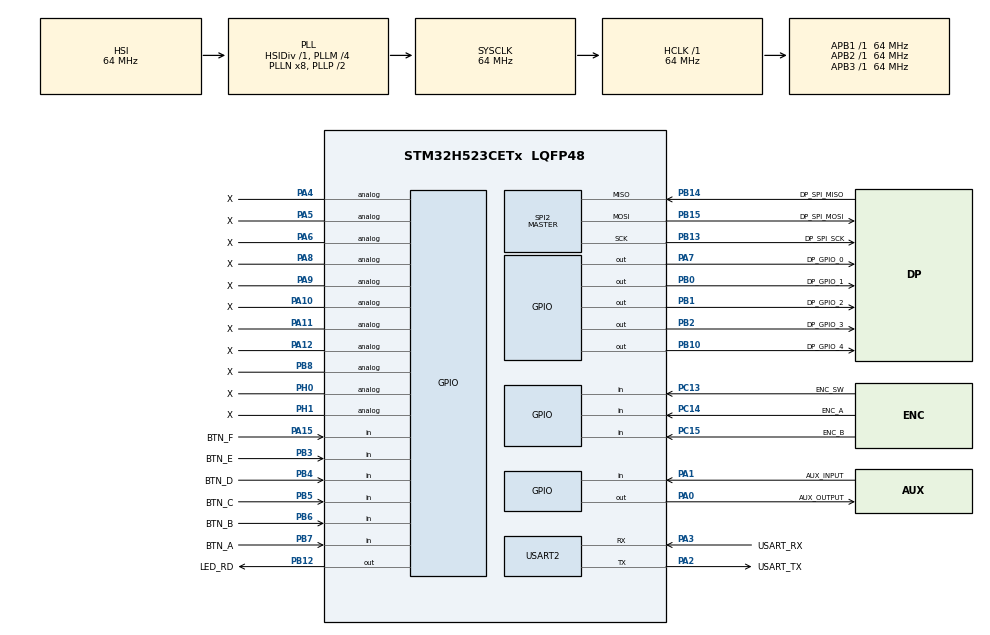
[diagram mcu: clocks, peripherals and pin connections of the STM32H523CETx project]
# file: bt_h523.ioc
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BOOTPATH.BootPathName=LEGACY
BOOTPATH.UserSelectedBootPath=LEGACY
CORTEX_M33_NS.Number-Cortex_Memory_Protection_Unit_Region0_OTP_RO_AREAS_Settings=MPU_REGION_NUMBER0
CORTEX_M33_NS.default_mode_Activation=1
CORTEX_M33_NS.userName=CORTEX_M33
GPDMA1.DIRECTION_GPDMACH3=DMA_MEMORY_TO_PERIPH
GPDMA1.IPHANDLE_GPDMACH2-SIMPLEREQUEST_GPDMACH2=__NULL
GPDMA1.IPHANDLE_GPDMACH3-SIMPLEREQUEST_GPDMACH3=__NULL
GPDMA1.REQUEST_GPDMACH2=GPDMA1_REQUEST_USART2_TX
GPDMA1.REQUEST_GPDMACH3=GPDMA1_REQUEST_USART2_RX
Mcu.Family=STM32H5
Mcu.Name=STM32H523CETx
Mcu.Package=LQFP48
NVIC.GPDMA1_Channel2_IRQn=true\:0\:0\:false\:false\:true\:false\:true\:true
NVIC.GPDMA1_Channel3_IRQn=true\:0\:0\:false\:false\:true\:false\:true\:true
NVIC.PriorityGroup=NVIC_PRIORITYGROUP_4
NVIC.USART2_IRQn=true\:0\:0\:false\:false\:true\:true\:true\:true
PA0.GPIO_Label=AUX_OUTPUT
PA0.Signal=GPIO_Output
PA1.GPIO_Label=AUX_INPUT
PA1.Signal=GPIO_Input
PA10.GPIO_Label=X
PA10.GPIO_Mode=GPIO_MODE_ANALOG
PA10.GPIO_Pd=GPIO_PULLDOWN
PA10.Signal=GPIO_Analog
PA11.GPIO_Label=X
PA11.GPIO_Mode=GPIO_MODE_ANALOG
PA11.GPIO_Pd=GPIO_PULLDOWN
PA11.Signal=GPIO_Analog
PA12.GPIO_Label=X
PA12.GPIO_Mode=GPIO_MODE_ANALOG
PA12.GPIO_Pd=GPIO_PULLDOWN
PA12.Signal=GPIO_Analog
PA13(JTMS/SWDIO).Mode=Serial_Wire
PA13(JTMS/SWDIO).Signal=DEBUG_JTMS-SWDIO
PA14(JTCK/SWCLK).Mode=Serial_Wire
PA14(JTCK/SWCLK).Signal=DEBUG_JTCK-SWCLK
PA15(JTDI).GPIO_Label=BTN_F
PA15(JTDI).Signal=GPIO_Input
PA2.GPIO_Label=USART_TX
PA2.Mode=Asynchronous
PA2.Signal=USART2_TX
PA3.GPIO_Label=USART_RX
PA3.Mode=Asynchronous
PA3.Signal=USART2_RX
PA4.GPIO_Label=X
PA4.GPIO_Mode=GPIO_MODE_ANALOG
PA4.GPIO_Pd=GPIO_PULLDOWN
PA4.Signal=GPIO_Analog
PA5.GPIO_Label=X
PA5.GPIO_Mode=GPIO_MODE_ANALOG
PA5.GPIO_Pd=GPIO_PULLDOWN
PA5.Signal=GPIO_Analog
PA6.GPIO_Label=X
PA6.GPIO_Mode=GPIO_MODE_ANALOG
PA6.GPIO_Pd=GPIO_PULLDOWN
PA6.Signal=GPIO_Analog
PA7.GPIO_Label=DP_GPIO_0
PA7.Signal=GPIO_Output
PA8.GPIO_Label=X
PA8.GPIO_Mode=GPIO_MODE_ANALOG
PA8.GPIO_Pd=GPIO_PULLDOWN
PA8.Signal=GPIO_Analog
PA9.GPIO_Label=X
PA9.GPIO_Mode=GPIO_MODE_ANALOG
PA9.GPIO_Pd=GPIO_PULLDOWN
PA9.Signal=GPIO_Analog
PB0.GPIO_Label=DP_GPIO_1
PB0.Signal=GPIO_Output
PB1.GPIO_Label=DP_GPIO_2
PB1.Signal=GPIO_Output
PB10.GPIO_Label=DP_GPIO_4
PB10.Signal=GPIO_Output
PB12.GPIO_Label=LED_RD
PB12.Signal=GPIO_Output
PB13.GPIO_Label=DP_SPI_SCK
PB13.Mode=Full_Duplex_Master
PB13.Signal=SPI2_SCK
PB14.GPIO_Label=DP_SPI_MISO
PB14.Mode=Full_Duplex_Master
PB14.Signal=SPI2_MISO
PB15.GPIO_Label=DP_SPI_MOSI
PB15.Mode=Full_Duplex_Master
PB15.Signal=SPI2_MOSI
PB2.GPIO_Label=DP_GPIO_3
PB2.Signal=GPIO_Output
PB3(JTDO/TRACESWO).GPIO_Label=BTN_E
PB3(JTDO/TRACESWO).Signal=GPIO_Input
PB4(NJTRST).GPIO_Label=BTN_D
PB4(NJTRST).Signal=GPIO_Input
PB5.GPIO_Label=BTN_C
PB5.Signal=GPIO_Input
PB6.GPIO_Label=BTN_B
PB6.Signal=GPIO_Input
PB7.GPIO_Label=BTN_A
PB7.Signal=GPIO_Input
PB8.GPIO_Label=X
PB8.GPIO_Mode=GPIO_MODE_ANALOG
PB8.GPIO_Pd=GPIO_PULLDOWN
PB8.Signal=GPIO_Analog
PC13.GPIO_Label=ENC_SW
PC13.Signal=GPIO_Input
PC14-OSC32_IN(OSC32_IN).GPIO_Label=ENC_A
PC14-OSC32_IN(OSC32_IN).Signal=GPIO_Input
PC15-OSC32_OUT(OSC32_OUT).GPIO_Label=ENC_B
PC15-OSC32_OUT(OSC32_OUT).Signal=GPIO_Input
PH0-OSC_IN(PH0).GPIO_Label=X
PH0-OSC_IN(PH0).GPIO_Mode=GPIO_MODE_ANALOG
PH0-OSC_IN(PH0).GPIO_Pd=GPIO_PULLDOWN
PH0-OSC_IN(PH0).Signal=GPIO_Analog
PH1-OSC_OUT(PH1).GPIO_Label=X
PH1-OSC_OUT(PH1).GPIO_Mode=GPIO_MODE_ANALOG
PH1-OSC_OUT(PH1).GPIO_Pd=GPIO_PULLDOWN
PH1-OSC_OUT(PH1).Signal=GPIO_Analog
ProjectManager.HeapSize=0x200
ProjectManager.StackSize=0x400
ProjectManager.TargetToolchain=CMake
RCC.ADCFreq_Value=64000000
RCC.AHBFreq_Value=64000000
RCC.APB1Freq_Value=64000000
RCC.APB1TimFreq_Value=64000000
RCC.APB2Freq_Value=64000000
RCC.APB2TimFreq_Value=64000000
RCC.APB3Freq_Value=64000000
RCC.CSI_VALUE=4000000
RCC.CortexFreq_Value=64000000
RCC.EPOD_VALUE=64000000
RCC.HCLKFreq_Value=64000000
RCC.HSE_VALUE=25000000
RCC.HSI48_VALUE=48000000
RCC.HSIDiv=RCC_HSI_DIV1
RCC.HSI_VALUE=64000000
RCC.LSE_VALUE=32768
RCC.LSIRC_VALUE=32000
RCC.PLL1Q=3
RCC.PLL2FRACN=0
RCC.PLL3FRACN=0
RCC.PLLFRACN=0
RCC.PLLM=4
RCC.PLLN=8
RCC.PLLSourceVirtual=RCC_PLL1_SOURCE_HSI
RCC.SYSCLKFreq_VALUE=64000000
RCC.SYSCLKSource=RCC_SYSCLKSOURCE_PLLCLK
RCC.USBFreq_Value=48000000
RCC.VCOOutputFreq_Value=128000000
SPI2.CalculateBaudRate=21.333332 MBits/s
SPI2.Direction=SPI_DIRECTION_2LINES
SPI2.Mode=SPI_MODE_MASTER
SPI2.VirtualType=VM_MASTER
USART2.VirtualMode-Asynchronous=VM_ASYNC
VP_BOOTPATH_VS_BOOTPATH.Mode=BP_Activate
VP_CORTEX_M33_NS_VS_Hclk.Mode=Hclk_Mode
VP_GPDMA1_VS_GPDMACH2.Mode=SIMPLEREQUEST_GPDMACH2
VP_GPDMA1_VS_GPDMACH3.Mode=SIMPLEREQUEST_GPDMACH3
VP_ICACHE_VS_ICACHE.Mode=DirectMappedCache
VP_MEMORYMAP_VS_MEMORYMAP.Mode=CurAppReg
VP_PWR_VS_LPOM.Mode=PowerOptimisation
VP_PWR_VS_SECSignals.Mode=Security/Privilege
board=custom

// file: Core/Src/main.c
/* USER CODE BEGIN Header */
/**
  ******************************************************************************
  * @file           : main.c
  * @brief          : Main program body
  ******************************************************************************
  * @attention
  *
  * Copyright (c) 2026 STMicroelectronics.
  * All rights reserved.
  *
  * This software is licensed under terms that can be found in the LICENSE file
  * in the root directory of this software component.
  * If no LICENSE file comes with this software, it is provided AS-IS.
  *
  ******************************************************************************
  */
/* USER CODE END Header */
#include "main.h"

SPI_HandleTypeDef hspi2;

UART_HandleTypeDef huart2;
DMA_HandleTypeDef handle_GPDMA1_Channel3;
DMA_HandleTypeDef handle_GPDMA1_Channel2;

void SystemClock_Config(void);
static void MPU_Config(void);
static void MX_GPIO_Init(void);
static void MX_GPDMA1_Init(void);
static void MX_ICACHE_Init(void);
static void MX_USART2_UART_Init(void);
static void MX_SPI2_Init(void);

int main(void)
{

  /* MCU Configuration--------------------------------------------------------*/

  /* MPU Configuration--------------------------------------------------------*/
  MPU_Config();

  /* Reset of all peripherals, Initializes the Flash interface and the Systick. */
  HAL_Init();

  /* Configure the system clock */
  SystemClock_Config();

  /* Initialize all configured peripherals */
  MX_GPIO_Init();
  MX_GPDMA1_Init();
  MX_ICACHE_Init();
  MX_USART2_UART_Init();
  MX_SPI2_Init();

  /* Infinite loop */
  while (1)
  {

    /* USER CODE BEGIN 3 */
    HAL_GPIO_TogglePin(LED_RD_GPIO_Port, LED_RD_Pin);
    HAL_Delay(500);
  }
  /* USER CODE END 3 */
}

void SystemClock_Config(void)
{
  RCC_OscInitTypeDef RCC_OscInitStruct = {0};
  RCC_ClkInitTypeDef RCC_ClkInitStruct = {0};

  /** Configure the main internal regulator output voltage
  */
  __HAL_PWR_VOLTAGESCALING_CONFIG(PWR_REGULATOR_VOLTAGE_SCALE3);

  while(!__HAL_PWR_GET_FLAG(PWR_FLAG_VOSRDY)) {}

  /** Initializes the RCC Oscillators according to the specified parameters
  * in the RCC_OscInitTypeDef structure.
  */
  RCC_OscInitStruct.OscillatorType = RCC_OSCILLATORTYPE_HSI;
  RCC_OscInitStruct.HSIState = RCC_HSI_ON;
  RCC_OscInitStruct.HSIDiv = RCC_HSI_DIV1;
  RCC_OscInitStruct.HSICalibrationValue = RCC_HSICALIBRATION_DEFAULT;
  RCC_OscInitStruct.PLL.PLLState = RCC_PLL_ON;
  RCC_OscInitStruct.PLL.PLLSource = RCC_PLL1_SOURCE_HSI;
  RCC_OscInitStruct.PLL.PLLM = 4;
  RCC_OscInitStruct.PLL.PLLN = 8;
  RCC_OscInitStruct.PLL.PLLP = 2;
  RCC_OscInitStruct.PLL.PLLQ = 3;
  RCC_OscInitStruct.PLL.PLLR = 2;
  RCC_OscInitStruct.PLL.PLLRGE = RCC_PLL1_VCIRANGE_3;
  RCC_OscInitStruct.PLL.PLLVCOSEL = RCC_PLL1_VCORANGE_WIDE;
  RCC_OscInitStruct.PLL.PLLFRACN = 0;
  if (HAL_RCC_OscConfig(&RCC_OscInitStruct) != HAL_OK)
  {
    Error_Handler();
  }

  /** Initializes the CPU, AHB and APB buses clocks
  */
  RCC_ClkInitStruct.ClockType = RCC_CLOCKTYPE_HCLK|RCC_CLOCKTYPE_SYSCLK
                              |RCC_CLOCKTYPE_PCLK1|RCC_CLOCKTYPE_PCLK2
                              |RCC_CLOCKTYPE_PCLK3;
  RCC_ClkInitStruct.SYSCLKSource = RCC_SYSCLKSOURCE_PLLCLK;
  RCC_ClkInitStruct.AHBCLKDivider = RCC_SYSCLK_DIV1;
  RCC_ClkInitStruct.APB1CLKDivider = RCC_HCLK_DIV1;
  RCC_ClkInitStruct.APB2CLKDivider = RCC_HCLK_DIV1;
  RCC_ClkInitStruct.APB3CLKDivider = RCC_HCLK_DIV1;

  if (HAL_RCC_ClockConfig(&RCC_ClkInitStruct, FLASH_LATENCY_3) != HAL_OK)
  {
    Error_Handler();
  }

  /** Configure the programming delay
  */
  __HAL_FLASH_SET_PROGRAM_DELAY(FLASH_PROGRAMMING_DELAY_1);
}

static void MX_GPDMA1_Init(void)
{

  /* Peripheral clock enable */
  __HAL_RCC_GPDMA1_CLK_ENABLE();

  /* GPDMA1 interrupt Init */
    HAL_NVIC_SetPriority(GPDMA1_Channel2_IRQn, 0, 0);
    HAL_NVIC_EnableIRQ(GPDMA1_Channel2_IRQn);
    HAL_NVIC_SetPriority(GPDMA1_Channel3_IRQn, 0, 0);
    HAL_NVIC_EnableIRQ(GPDMA1_Channel3_IRQn);

}

static void MX_ICACHE_Init(void)
{

  /** Enable instruction cache in 1-way (direct mapped cache)
  */
  if (HAL_ICACHE_ConfigAssociativityMode(ICACHE_1WAY) != HAL_OK)
  {
    Error_Handler();
  }
  if (HAL_ICACHE_Enable() != HAL_OK)
  {
    Error_Handler();
  }

}

static void MX_SPI2_Init(void)
{

  /* SPI2 parameter configuration*/
  hspi2.Instance = SPI2;
  hspi2.Init.Mode = SPI_MODE_MASTER;
  hspi2.Init.Direction = SPI_DIRECTION_2LINES;
  hspi2.Init.DataSize = SPI_DATASIZE_4BIT;
  hspi2.Init.CLKPolarity = SPI_POLARITY_LOW;
  hspi2.Init.CLKPhase = SPI_PHASE_1EDGE;
  hspi2.Init.NSS = SPI_NSS_SOFT;
  hspi2.Init.BaudRatePrescaler = SPI_BAUDRATEPRESCALER_2;
  hspi2.Init.FirstBit = SPI_FIRSTBIT_MSB;
  hspi2.Init.TIMode = SPI_TIMODE_DISABLE;
  hspi2.Init.CRCCalculation = SPI_CRCCALCULATION_DISABLE;
  hspi2.Init.CRCPolynomial = 0x7;
  hspi2.Init.NSSPMode = SPI_NSS_PULSE_ENABLE;
  hspi2.Init.NSSPolarity = SPI_NSS_POLARITY_LOW;
  hspi2.Init.FifoThreshold = SPI_FIFO_THRESHOLD_01DATA;
  hspi2.Init.MasterSSIdleness = SPI_MASTER_SS_IDLENESS_00CYCLE;
  hspi2.Init.MasterInterDataIdleness = SPI_MASTER_INTERDATA_IDLENESS_00CYCLE;
  hspi2.Init.MasterReceiverAutoSusp = SPI_MASTER_RX_AUTOSUSP_DISABLE;
  hspi2.Init.MasterKeepIOState = SPI_MASTER_KEEP_IO_STATE_DISABLE;
  hspi2.Init.IOSwap = SPI_IO_SWAP_DISABLE;
  hspi2.Init.ReadyMasterManagement = SPI_RDY_MASTER_MANAGEMENT_INTERNALLY;
  hspi2.Init.ReadyPolarity = SPI_RDY_POLARITY_HIGH;
  if (HAL_SPI_Init(&hspi2) != HAL_OK)
  {
    Error_Handler();
  }

}

static void MX_USART2_UART_Init(void)
{

  huart2.Instance = USART2;
  huart2.Init.BaudRate = 115200;
  huart2.Init.WordLength = UART_WORDLENGTH_8B;
  huart2.Init.StopBits = UART_STOPBITS_1;
  huart2.Init.Parity = UART_PARITY_NONE;
  huart2.Init.Mode = UART_MODE_TX_RX;
  huart2.Init.HwFlowCtl = UART_HWCONTROL_NONE;
  huart2.Init.OverSampling = UART_OVERSAMPLING_16;
  huart2.Init.OneBitSampling = UART_ONE_BIT_SAMPLE_DISABLE;
  huart2.Init.ClockPrescaler = UART_PRESCALER_DIV1;
  huart2.AdvancedInit.AdvFeatureInit = UART_ADVFEATURE_NO_INIT;
  if (HAL_UART_Init(&huart2) != HAL_OK)
  {
    Error_Handler();
  }
  if (HAL_UARTEx_SetTxFifoThreshold(&huart2, UART_TXFIFO_THRESHOLD_1_8) != HAL_OK)
  {
    Error_Handler();
  }
  if (HAL_UARTEx_SetRxFifoThreshold(&huart2, UART_RXFIFO_THRESHOLD_1_8) != HAL_OK)
  {
    Error_Handler();
  }
  if (HAL_UARTEx_DisableFifoMode(&huart2) != HAL_OK)
  {
    Error_Handler();
  }

}

static void MX_GPIO_Init(void)
{
  GPIO_InitTypeDef GPIO_InitStruct = {0};

  /* GPIO Ports Clock Enable */
  __HAL_RCC_GPIOC_CLK_ENABLE();
  __HAL_RCC_GPIOH_CLK_ENABLE();
  __HAL_RCC_GPIOA_CLK_ENABLE();
  __HAL_RCC_GPIOB_CLK_ENABLE();

  /*Configure GPIO pin Output Level */
  HAL_GPIO_WritePin(GPIOA, AUX_OUTPUT_Pin|DP_GPIO_0_Pin, GPIO_PIN_RESET);

  /*Configure GPIO pin Output Level */
  HAL_GPIO_WritePin(GPIOB, DP_GPIO_1_Pin|DP_GPIO_2_Pin|DP_GPIO_3_Pin|DP_GPIO_4_Pin
                          |LED_RD_Pin, GPIO_PIN_RESET);

  /*Configure GPIO pins : ENC_SW_Pin ENC_A_Pin ENC_B_Pin */
  GPIO_InitStruct.Pin = ENC_SW_Pin|ENC_A_Pin|ENC_B_Pin;
  GPIO_InitStruct.Mode = GPIO_MODE_INPUT;
  GPIO_InitStruct.Pull = GPIO_NOPULL;
  HAL_GPIO_Init(GPIOC, &GPIO_InitStruct);

  /*Configure GPIO pins : X_Pin XH1_Pin */
  GPIO_InitStruct.Pin = X_Pin|XH1_Pin;
  GPIO_InitStruct.Mode = GPIO_MODE_ANALOG;
  GPIO_InitStruct.Pull = GPIO_PULLDOWN;
  HAL_GPIO_Init(GPIOH, &GPIO_InitStruct);

  /*Configure GPIO pins : AUX_OUTPUT_Pin DP_GPIO_0_Pin */
  GPIO_InitStruct.Pin = AUX_OUTPUT_Pin|DP_GPIO_0_Pin;
  GPIO_InitStruct.Mode = GPIO_MODE_OUTPUT_PP;
  GPIO_InitStruct.Pull = GPIO_NOPULL;
  GPIO_InitStruct.Speed = GPIO_SPEED_FREQ_LOW;
  HAL_GPIO_Init(GPIOA, &GPIO_InitStruct);

  /*Configure GPIO pins : AUX_INPUT_Pin BTN_F_Pin */
  GPIO_InitStruct.Pin = AUX_INPUT_Pin|BTN_F_Pin;
  GPIO_InitStruct.Mode = GPIO_MODE_INPUT;
  GPIO_InitStruct.Pull = GPIO_NOPULL;
  HAL_GPIO_Init(GPIOA, &GPIO_InitStruct);

  /*Configure GPIO pins : XA4_Pin XA5_Pin XA6_Pin XA8_Pin
                           XA9_Pin XA10_Pin XA11_Pin XA12_Pin */
  GPIO_InitStruct.Pin = XA4_Pin|XA5_Pin|XA6_Pin|XA8_Pin
                          |XA9_Pin|XA10_Pin|XA11_Pin|XA12_Pin;
  GPIO_InitStruct.Mode = GPIO_MODE_ANALOG;
  GPIO_InitStruct.Pull = GPIO_PULLDOWN;
  HAL_GPIO_Init(GPIOA, &GPIO_InitStruct);

  /*Configure GPIO pins : DP_GPIO_1_Pin DP_GPIO_2_Pin DP_GPIO_3_Pin DP_GPIO_4_Pin
                           LED_RD_Pin */
  GPIO_InitStruct.Pin = DP_GPIO_1_Pin|DP_GPIO_2_Pin|DP_GPIO_3_Pin|DP_GPIO_4_Pin
                          |LED_RD_Pin;
  GPIO_InitStruct.Mode = GPIO_MODE_OUTPUT_PP;
  GPIO_InitStruct.Pull = GPIO_NOPULL;
  GPIO_InitStruct.Speed = GPIO_SPEED_FREQ_LOW;
  HAL_GPIO_Init(GPIOB, &GPIO_InitStruct);

  /*Configure GPIO pins : BTN_E_Pin BTN_D_Pin BTN_C_Pin BTN_B_Pin
                           BTN_A_Pin */
  GPIO_InitStruct.Pin = BTN_E_Pin|BTN_D_Pin|BTN_C_Pin|BTN_B_Pin
                          |BTN_A_Pin;
  GPIO_InitStruct.Mode = GPIO_MODE_INPUT;
  GPIO_InitStruct.Pull = GPIO_NOPULL;
  HAL_GPIO_Init(GPIOB, &GPIO_InitStruct);

  /*Configure GPIO pin : XB8_Pin */
  GPIO_InitStruct.Pin = XB8_Pin;
  GPIO_InitStruct.Mode = GPIO_MODE_ANALOG;
  GPIO_InitStruct.Pull = GPIO_PULLDOWN;
  HAL_GPIO_Init(XB8_GPIO_Port, &GPIO_InitStruct);

}

 /* MPU Configuration */

void MPU_Config(void)
{
  MPU_Region_InitTypeDef MPU_InitStruct = {0};
  MPU_Attributes_InitTypeDef MPU_AttributesInit = {0};

  /* Disables the MPU */
  HAL_MPU_Disable();

  /** Initializes and configures the Region 0 and the memory to be protected
  */
  MPU_InitStruct.Enable = MPU_REGION_ENABLE;
  MPU_InitStruct.Number = MPU_REGION_NUMBER0;
  MPU_InitStruct.BaseAddress = 0x08FFF000;
  MPU_InitStruct.LimitAddress = 0x08FFFFFF;
  MPU_InitStruct.AttributesIndex = MPU_ATTRIBUTES_NUMBER0;
  MPU_InitStruct.AccessPermission = MPU_REGION_ALL_RO;
  MPU_InitStruct.DisableExec = MPU_INSTRUCTION_ACCESS_DISABLE;
  MPU_InitStruct.IsShareable = MPU_ACCESS_NOT_SHAREABLE;

  HAL_MPU_ConfigRegion(&MPU_InitStruct);

  /** Initializes and configures the Attribute 0 and the memory to be protected
  */
  MPU_AttributesInit.Number = MPU_ATTRIBUTES_NUMBER0;
  MPU_AttributesInit.Attributes = INNER_OUTER(MPU_NOT_CACHEABLE);

  HAL_MPU_ConfigMemoryAttributes(&MPU_AttributesInit);
  /* Enables the MPU */
  HAL_MPU_Enable(MPU_PRIVILEGED_DEFAULT);

}

void Error_Handler(void)
{
  __disable_irq();
  while (1)
  {
  }
}
